# BL808 register map
File version: 0.1
Registers are access not given, no defined reset value unless marked. A register's access mark holds for its fields unless they carry their own. Offsets are from the block's base; [hi:lo] are bit positions; {n}, {i} and the like mark numbered series.

## AUDIO
Base 0x20055000
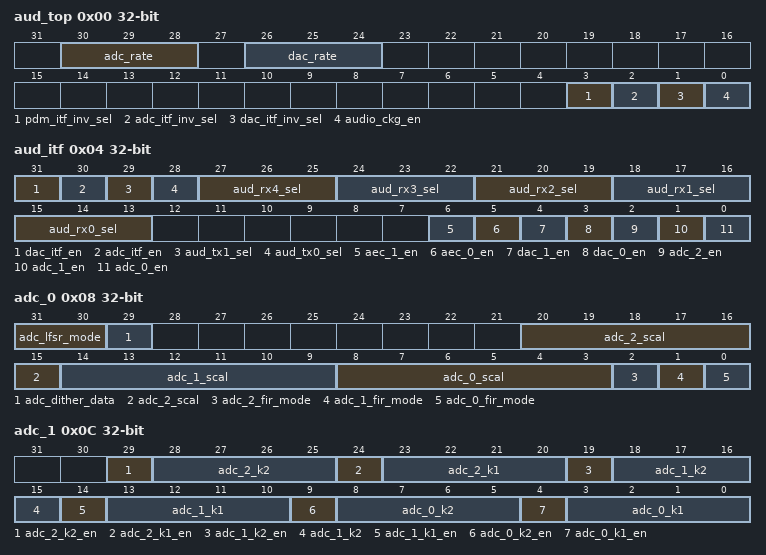
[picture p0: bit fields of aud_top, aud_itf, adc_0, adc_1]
0x00 aud_top
  [30:28] adc_rate rw, [26:24] dac_rate rw, [3] pdm_itf_inv_sel rw, [2] adc_itf_inv_sel rw, [1] dac_itf_inv_sel rw, [0] audio_ckg_en rw
0x04 aud_itf
  [31] dac_itf_en rw, [30] adc_itf_en rw, [29] aud_tx1_sel rw, [28] aud_tx0_sel rw, [3n+15:3n+13] aud_rx{n}_sel rw (n=0..4), [6] aec_1_en rw, [5] aec_0_en rw, [4] dac_1_en rw, [3] dac_0_en rw, [2] adc_2_en rw, [1] adc_1_en rw, [0] adc_0_en rw
0x08 adc_0
  [31:30] adc_lfsr_mode rw, [29] adc_dither_data ro, [20:15] adc_2_scal rw, [14:9] adc_1_scal rw, [8:3] adc_0_scal rw, [2] adc_2_fir_mode rw, [1] adc_1_fir_mode rw, [0] adc_0_fir_mode rw
0x0C adc_1
  [29] adc_2_k2_en rw, [28:25] adc_2_k2 rw, [24] adc_2_k1_en rw, [23:20] adc_2_k1 rw, [19] adc_1_k2_en rw, [18:15] adc_1_k2 rw, [14] adc_1_k1_en rw, [13:10] adc_1_k1 rw, [9] adc_0_k2_en rw, [8:5] adc_0_k2 rw, [4] adc_0_k1_en rw, [3:0] adc_0_k1 rw
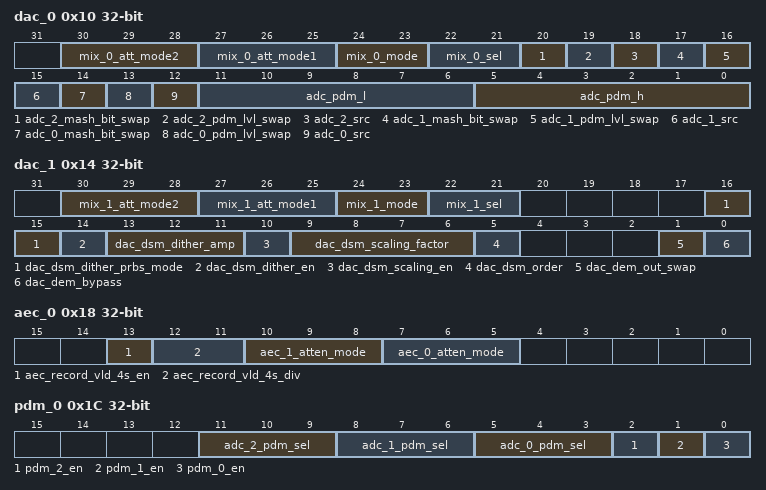
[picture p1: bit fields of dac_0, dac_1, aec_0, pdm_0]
0x10 dac_0
  [30:28] mix_0_att_mode2 rw, [27:25] mix_0_att_mode1 rw, [24:23] mix_0_mode rw, [22:21] mix_0_sel rw, [20] adc_2_mash_bit_swap rw, [19] adc_2_pdm_lvl_swap rw, [18] adc_2_src rw, [17] adc_1_mash_bit_swap rw, [16] adc_1_pdm_lvl_swap rw, [15] adc_1_src rw, [14] adc_0_mash_bit_swap rw, [13] adc_0_pdm_lvl_swap rw, [12] adc_0_src rw, [11:6] adc_pdm_l rw, [5:0] adc_pdm_h rw
0x14 dac_1
  [30:28] mix_1_att_mode2 rw, [27:25] mix_1_att_mode1 rw, [24:23] mix_1_mode rw, [22:21] mix_1_sel rw, [16:15] dac_dsm_dither_prbs_mode rw, [14] dac_dsm_dither_en rw, [13:11] dac_dsm_dither_amp rw, [10] dac_dsm_scaling_en rw, [9:6] dac_dsm_scaling_factor rw, [5] dac_dsm_order rw, [1] dac_dem_out_swap rw, [0] dac_dem_bypass rw
0x18 aec_0
  [13] aec_record_vld_4s_en rw, [12:11] aec_record_vld_4s_div rw, [10:8] aec_1_atten_mode rw, [7:5] aec_0_atten_mode rw
0x1C pdm_0
  [11:9] adc_2_pdm_sel rw, [8:6] adc_1_pdm_sel rw, [5:3] adc_0_pdm_sel rw, [2] pdm_2_en rw, [1] pdm_1_en rw, [0] pdm_0_en rw
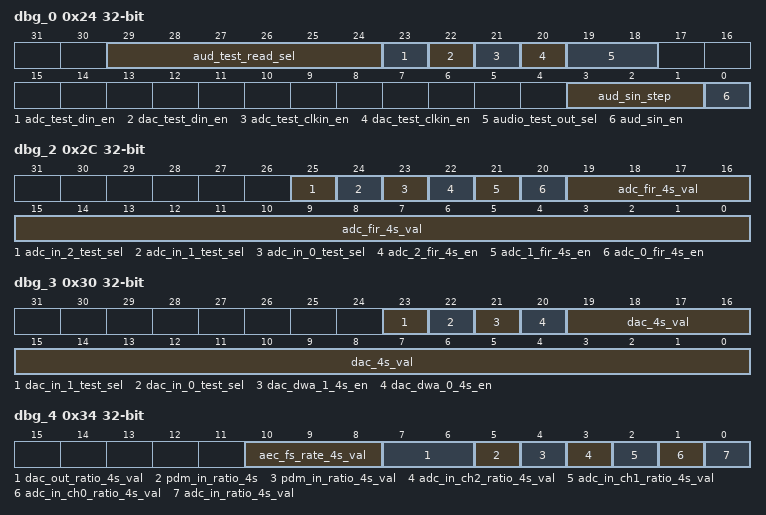
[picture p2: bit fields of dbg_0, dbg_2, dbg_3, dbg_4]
0x24 dbg_0
  [29:24] aud_test_read_sel rw, [23] adc_test_din_en rw, [22] dac_test_din_en rw, [21] adc_test_clkin_en rw, [20] dac_test_clkin_en rw, [19:18] audio_test_out_sel rw, [3:1] aud_sin_step rw, [0] aud_sin_en rw
0x28 dbg_1 ro
  [31:0] aud_test_read
0x2C dbg_2
  [25] adc_in_2_test_sel rw, [24] adc_in_1_test_sel rw, [23] adc_in_0_test_sel rw, [22] adc_2_fir_4s_en rw, [21] adc_1_fir_4s_en rw, [20] adc_0_fir_4s_en rw, [19:0] adc_fir_4s_val rw
0x30 dbg_3
  [23] dac_in_1_test_sel rw, [22] dac_in_0_test_sel rw, [21] dac_dwa_1_4s_en rw, [20] dac_dwa_0_4s_en rw, [19:0] dac_4s_val rw
0x34 dbg_4
  [10:8] aec_fs_rate_4s_val rw, [7:6] dac_out_ratio_4s_val rw, [5] pdm_in_ratio_4s rw, [4] pdm_in_ratio_4s_val rw, [3] adc_in_ch2_ratio_4s_val rw, [2] adc_in_ch1_ratio_4s_val rw, [1] adc_in_ch0_ratio_4s_val rw, [0] adc_in_ratio_4s_val rw
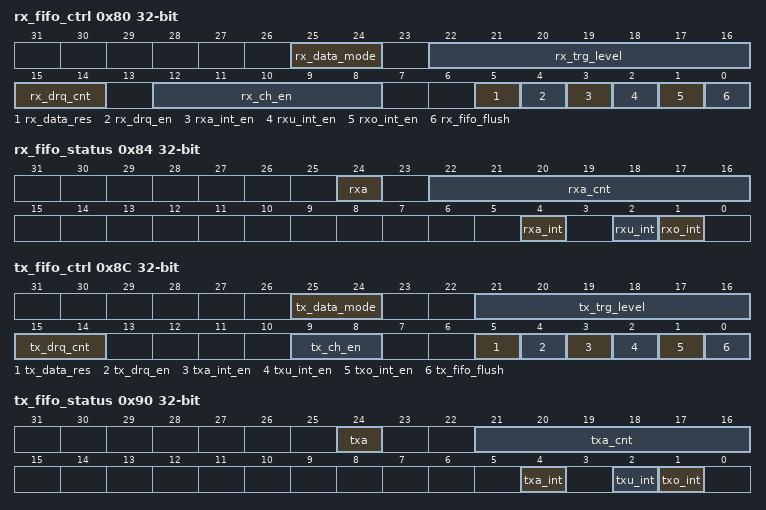
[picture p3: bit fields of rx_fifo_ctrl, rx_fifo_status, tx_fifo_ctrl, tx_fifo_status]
0x80 rx_fifo_ctrl
  [25:24] rx_data_mode rw, [22:16] rx_trg_level rw, [15:14] rx_drq_cnt rw, [12:8] rx_ch_en rw, [5] rx_data_res rw, [4] rx_drq_en rw, [3] rxa_int_en rw, [2] rxu_int_en rw, [1] rxo_int_en rw, [0] rx_fifo_flush write-once
0x84 rx_fifo_status
  [24] rxa ro, [22:16] rxa_cnt ro, [4] rxa_int ro, [2] rxu_int ro, [1] rxo_int ro
0x88 rx_fifo_data ro
  [31:0] rx_data
0x8C tx_fifo_ctrl
  [25:24] tx_data_mode rw, [21:16] tx_trg_level rw, [15:14] tx_drq_cnt rw, [9:8] tx_ch_en rw, [5] tx_data_res rw, [4] tx_drq_en rw, [3] txa_int_en rw, [2] txu_int_en rw, [1] txo_int_en rw, [0] tx_fifo_flush write-once
0x90 tx_fifo_status
  [24] txa ro, [21:16] txa_cnt ro, [4] txa_int ro, [2] txu_int ro, [1] txo_int ro
0x94 tx_fifo_data wo
  [31:0] tx_data
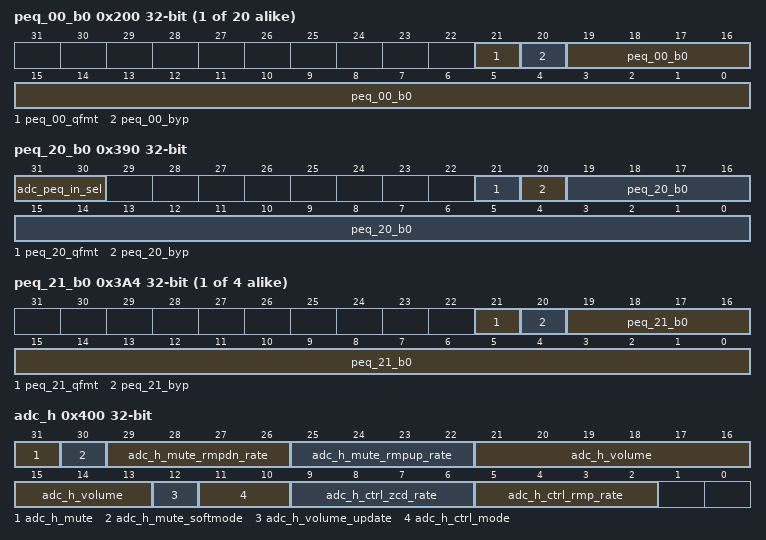
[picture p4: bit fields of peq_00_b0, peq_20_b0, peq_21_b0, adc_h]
{0x200+0x14*i} peq_{i:02}_b0 (i=0..19)
  [21] peq_{i:02}_qfmt rw, [20] peq_{i:02}_byp rw, [19:0] peq_{i:02}_b0 rw
{0x204+0x14*i} peq_{i:02}_b1 (i=0..24)
  [19:0] peq_{i:02}_b1 rw
{0x208+0x14*i} peq_{i:02}_b2 (i=0..24)
  [19:0] peq_{i:02}_b2 rw
{0x20C+0x14*i} peq_{i:02}_a1 (i=0..24)
  [19:0] peq_{i:02}_a1 rw
{0x210+0x14*i} peq_{i:02}_a2 (i=0..24)
  [19:0] peq_{i:02}_a2 rw
0x390 peq_20_b0
  [31:30] adc_peq_in_sel rw, [21] peq_20_qfmt rw, [20] peq_20_byp rw, [19:0] peq_20_b0 rw
{0x200+0x14*i} peq_{i}_b0 (i=21..24)
  [21] peq_{i}_qfmt rw, [20] peq_{i}_byp rw, [19:0] peq_{i}_b0 rw
0x400 adc_h
  [31] adc_h_mute rw, [30] adc_h_mute_softmode rw, [29:26] adc_h_mute_rmpdn_rate rw, [25:22] adc_h_mute_rmpup_rate rw, [21:13] adc_h_volume ro, [12] adc_h_volume_update rw, [11:10] adc_h_ctrl_mode rw, [9:6] adc_h_ctrl_zcd_rate rw, [5:2] adc_h_ctrl_rmp_rate rw
0x404 adc_h_misc
  [31:28] adc_h_ctrl_zcd_timeout rw
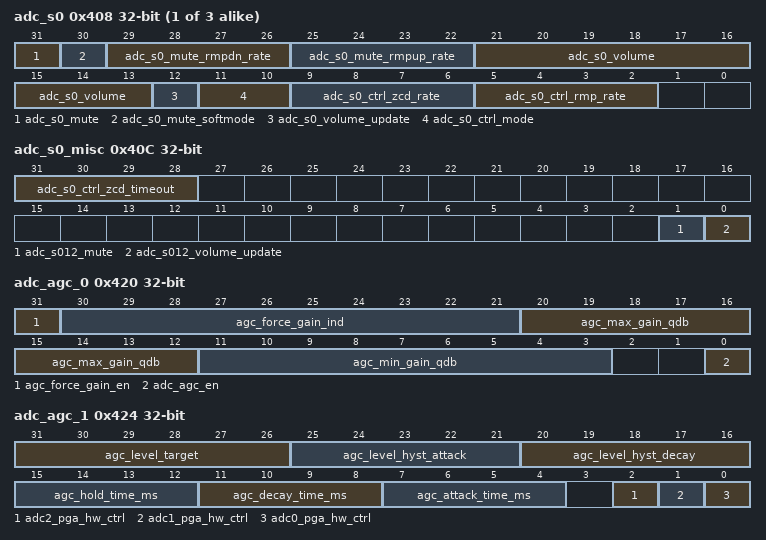
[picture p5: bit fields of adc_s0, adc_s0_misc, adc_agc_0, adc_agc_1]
{0x408+8i} adc_s{i} (i=0..2)
  [31] adc_s{i}_mute rw, [30] adc_s{i}_mute_softmode rw, [29:26] adc_s{i}_mute_rmpdn_rate rw, [25:22] adc_s{i}_mute_rmpup_rate rw, [21:13] adc_s{i}_volume rw, [12] adc_s{i}_volume_update rw, [11:10] adc_s{i}_ctrl_mode rw, [9:6] adc_s{i}_ctrl_zcd_rate rw, [5:2] adc_s{i}_ctrl_rmp_rate rw
0x40C adc_s0_misc
  [31:28] adc_s0_ctrl_zcd_timeout rw, [1] adc_s012_mute rw, [0] adc_s012_volume_update rw
0x414 adc_s1_misc
  [31:28] adc_s1_ctrl_zcd_timeout rw
0x41C adc_s2_misc
  [31:28] adc_s2_ctrl_zcd_timeout rw
0x420 adc_agc_0
  [31] agc_force_gain_en rw, [30:21] agc_force_gain_ind rw, [20:12] agc_max_gain_qdb rw, [11:3] agc_min_gain_qdb rw, [0] adc_agc_en rw
0x424 adc_agc_1
  [31:26] agc_level_target rw, [25:21] agc_level_hyst_attack rw, [20:16] agc_level_hyst_decay rw, [15:12] agc_hold_time_ms rw, [11:8] agc_decay_time_ms rw, [7:4] agc_attack_time_ms rw, [2] adc2_pga_hw_ctrl rw, [1] adc1_pga_hw_ctrl rw, [0] adc0_pga_hw_ctrl rw
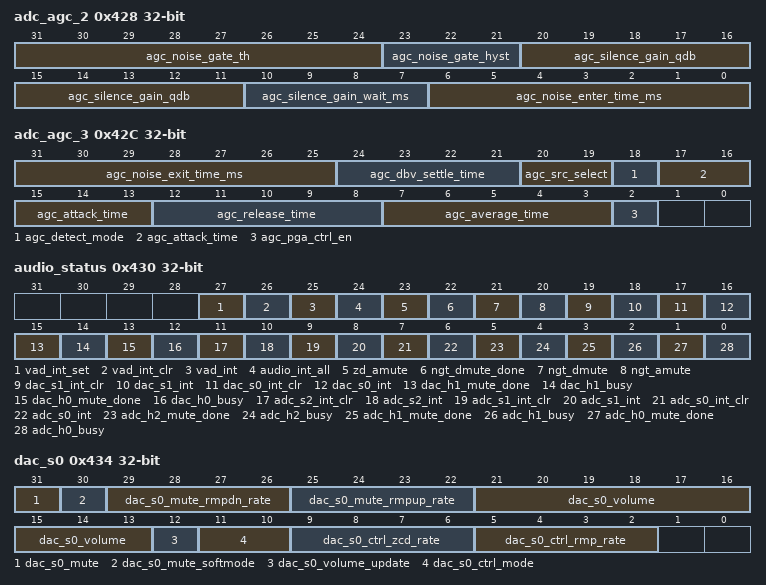
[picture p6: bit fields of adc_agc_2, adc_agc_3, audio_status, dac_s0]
0x428 adc_agc_2 rw
  [31:24] agc_noise_gate_th, [23:21] agc_noise_gate_hyst, [20:11] agc_silence_gain_qdb, [10:7] agc_silence_gain_wait_ms, [6:0] agc_noise_enter_time_ms
0x42C adc_agc_3
  [31:25] agc_noise_exit_time_ms rw, [24:21] agc_dbv_settle_time rw, [20:19] agc_src_select rw, [18] agc_detect_mode rw, [17:13] agc_attack_time rw, [12:8] agc_release_time rw, [7:3] agc_average_time rw, [2] agc_pga_ctrl_en rw
0x430 audio_status
  [27] vad_int_set rw, [26] vad_int_clr rw, [25] vad_int ro, [24] audio_int_all ro, [23] zd_amute ro, [22] ngt_dmute_done ro, [21] ngt_dmute ro, [20] ngt_amute ro, [19] dac_s1_int_clr rw, [18] dac_s1_int ro, [17] dac_s0_int_clr rw, [16] dac_s0_int ro, [15] dac_h1_mute_done ro, [14] dac_h1_busy ro, [13] dac_h0_mute_done ro, [12] dac_h0_busy ro, [11] adc_s2_int_clr rw, [10] adc_s2_int ro, [9] adc_s1_int_clr rw, [8] adc_s1_int ro, [7] adc_s0_int_clr rw, [6] adc_s0_int ro, [5] adc_h2_mute_done ro, [4] adc_h2_busy ro, [3] adc_h1_mute_done ro, [2] adc_h1_busy ro, [1] adc_h0_mute_done ro, [0] adc_h0_busy ro
0x434 dac_s0
  [31] dac_s0_mute rw, [30] dac_s0_mute_softmode rw, [29:26] dac_s0_mute_rmpdn_rate rw, [25:22] dac_s0_mute_rmpup_rate rw, [21:13] dac_s0_volume rw, [12] dac_s0_volume_update rw, [11:10] dac_s0_ctrl_mode rw, [9:6] dac_s0_ctrl_zcd_rate rw, [5:2] dac_s0_ctrl_rmp_rate rw
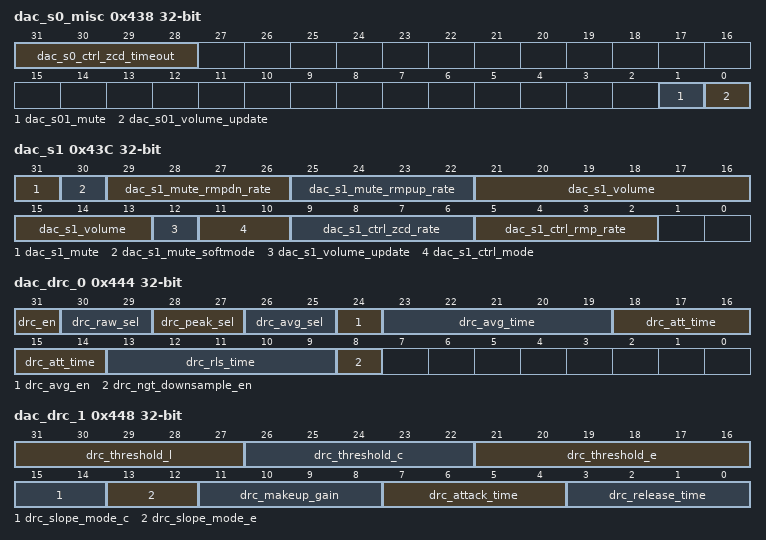
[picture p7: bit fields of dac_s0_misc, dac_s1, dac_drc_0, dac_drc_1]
0x438 dac_s0_misc
  [31:28] dac_s0_ctrl_zcd_timeout rw, [1] dac_s01_mute rw, [0] dac_s01_volume_update rw
0x43C dac_s1
  [31] dac_s1_mute rw, [30] dac_s1_mute_softmode rw, [29:26] dac_s1_mute_rmpdn_rate rw, [25:22] dac_s1_mute_rmpup_rate rw, [21:13] dac_s1_volume rw, [12] dac_s1_volume_update rw, [11:10] dac_s1_ctrl_mode rw, [9:6] dac_s1_ctrl_zcd_rate rw, [5:2] dac_s1_ctrl_rmp_rate rw
0x440 dac_s1_misc
  [31:28] dac_s1_ctrl_zcd_timeout rw
0x444 dac_drc_0
  [31] drc_en rw, [30:29] drc_raw_sel rw, [28:27] drc_peak_sel rw, [26:25] drc_avg_sel rw, [24] drc_avg_en rw, [23:19] drc_avg_time rw, [18:14] drc_att_time rw, [13:9] drc_rls_time rw, [8] drc_ngt_downsample_en rw
0x448 dac_drc_1 rw
  [31:27] drc_threshold_l, [26:22] drc_threshold_c, [21:16] drc_threshold_e, [15:14] drc_slope_mode_c, [13:12] drc_slope_mode_e, [11:8] drc_makeup_gain, [7:4] drc_attack_time, [3:0] drc_release_time
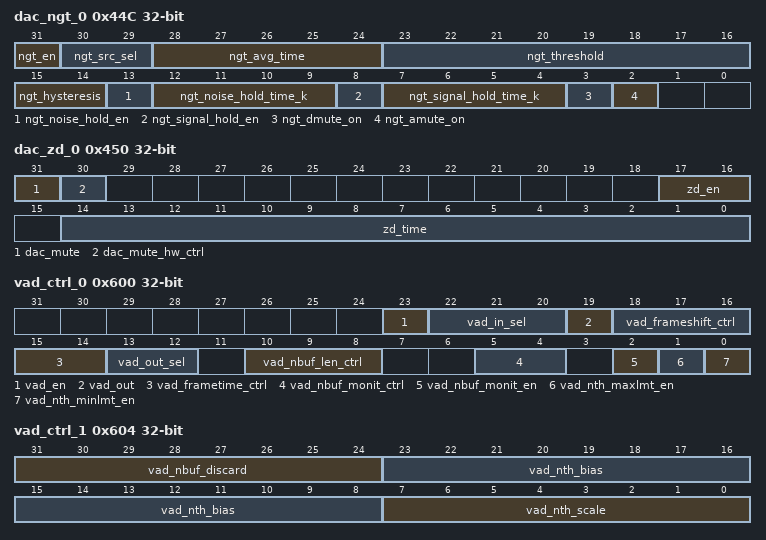
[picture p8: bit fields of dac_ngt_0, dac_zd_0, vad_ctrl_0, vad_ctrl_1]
0x44C dac_ngt_0
  [31] ngt_en rw, [30:29] ngt_src_sel rw, [28:24] ngt_avg_time rw, [23:16] ngt_threshold rw, [15:14] ngt_hysteresis rw, [13] ngt_noise_hold_en rw, [12:9] ngt_noise_hold_time_k rw, [8] ngt_signal_hold_en rw, [7:4] ngt_signal_hold_time_k rw, [3] ngt_dmute_on rw, [2] ngt_amute_on rw
0x450 dac_zd_0
  [31] dac_mute rw, [30] dac_mute_hw_ctrl rw, [17:16] zd_en rw, [14:0] zd_time rw
0x600 vad_ctrl_0
  [23] vad_en rw, [22:20] vad_in_sel rw, [19] vad_out ro, [18:16] vad_frameshift_ctrl rw, [15:14] vad_frametime_ctrl rw, [13:12] vad_out_sel rw, [10:8] vad_nbuf_len_ctrl rw, [5:4] vad_nbuf_monit_ctrl rw, [2] vad_nbuf_monit_en rw, [1] vad_nth_maxlmt_en rw, [0] vad_nth_minlmt_en rw
0x604 vad_ctrl_1 rw
  [31:24] vad_nbuf_discard, [23:8] vad_nth_bias, [7:0] vad_nth_scale
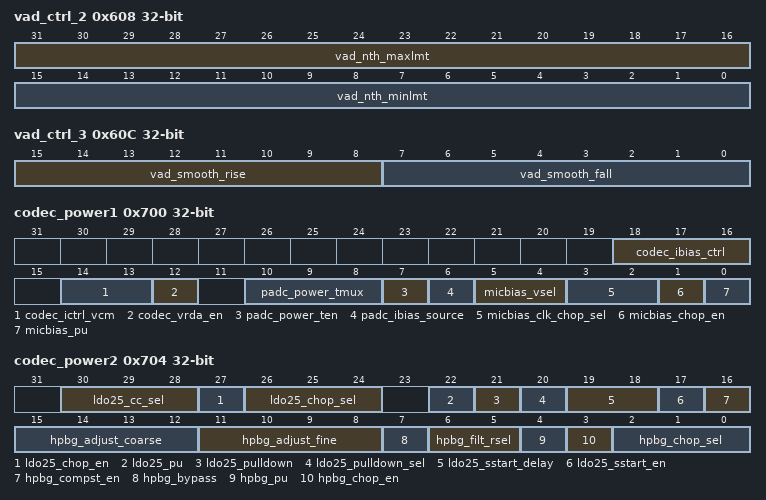
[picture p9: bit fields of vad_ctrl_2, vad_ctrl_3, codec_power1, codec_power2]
0x608 vad_ctrl_2 rw
  [31:16] vad_nth_maxlmt, [15:0] vad_nth_minlmt
0x60C vad_ctrl_3
  [15:8] vad_smooth_rise rw, [7:0] vad_smooth_fall rw
0x610 vad_ctrl_4
  [23:0] vad_ek ro
0x614 vad_ctrl_5
  [23:0] vad_noise_th ro
0x700 codec_power1
  [18:16] codec_ibias_ctrl rw, [14:13] codec_ictrl_vcm rw, [12] codec_vrda_en rw, [10:8] padc_power_tmux rw, [7] padc_power_ten rw, [6] padc_ibias_source rw, [5:4] micbias_vsel rw, [3:2] micbias_clk_chop_sel rw, [1] micbias_chop_en rw, [0] micbias_pu rw
0x704 codec_power2
  [30:28] ldo25_cc_sel rw, [27] ldo25_chop_en rw, [26:24] ldo25_chop_sel rw, [22] ldo25_pu rw, [21] ldo25_pulldown rw, [20] ldo25_pulldown_sel rw, [19:18] ldo25_sstart_delay rw, [17] ldo25_sstart_en rw, [16] hpbg_compst_en rw, [15:12] hpbg_adjust_coarse rw, [11:8] hpbg_adjust_fine rw, [7] hpbg_bypass rw, [6:5] hpbg_filt_rsel rw, [4] hpbg_pu rw, [3] hpbg_chop_en rw, [2:0] hpbg_chop_sel rw
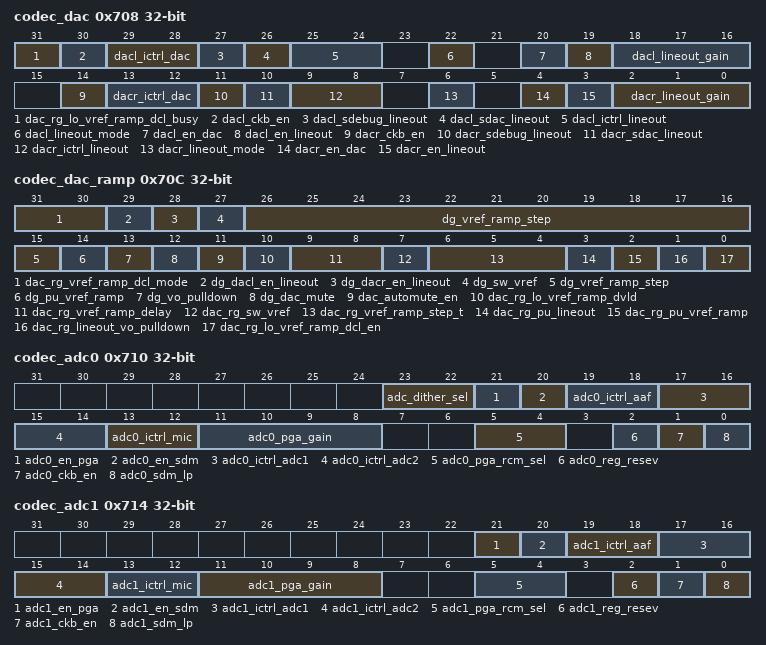
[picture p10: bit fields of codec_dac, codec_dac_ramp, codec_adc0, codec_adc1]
0x708 codec_dac
  [31] dac_rg_lo_vref_ramp_dcl_busy ro, [30] dacl_ckb_en rw, [29:28] dacl_ictrl_dac rw, [27] dacl_sdebug_lineout rw, [26] dacl_sdac_lineout rw, [25:24] dacl_ictrl_lineout rw, [22] dacl_lineout_mode rw, [20] dacl_en_dac rw, [19] dacl_en_lineout rw, [18:16] dacl_lineout_gain rw, [14] dacr_ckb_en rw, [13:12] dacr_ictrl_dac rw, [11] dacr_sdebug_lineout rw, [10] dacr_sdac_lineout rw, [9:8] dacr_ictrl_lineout rw, [6] dacr_lineout_mode rw, [4] dacr_en_dac rw, [3] dacr_en_lineout rw, [2:0] dacr_lineout_gain rw
0x70C codec_dac_ramp access per field
  [31:30] dac_rg_vref_ramp_dcl_mode rw, [29] dg_dacl_en_lineout ro, [28] dg_dacr_en_lineout ro, [27] dg_sw_vref ro, [26:15] dg_vref_ramp_step ro, [14] dg_pu_vref_ramp ro, [13] dg_vo_pulldown ro, [12] dg_dac_mute ro, [11] dac_automute_en rw, [10] dac_rg_lo_vref_ramp_dvld ro, [9:8] dac_rg_vref_ramp_delay rw, [7] dac_rg_sw_vref rw, [6:4] dac_rg_vref_ramp_step_t rw, [3] dac_rg_pu_lineout rw, [2] dac_rg_pu_vref_ramp rw, [1] dac_rg_lineout_vo_pulldown rw, [0] dac_rg_lo_vref_ramp_dcl_en rw
0x710 codec_adc0
  [23:22] adc_dither_sel rw, [21] adc0_en_pga rw, [20] adc0_en_sdm rw, [19:18] adc0_ictrl_aaf rw, [17:16] adc0_ictrl_adc1 rw, [15:14] adc0_ictrl_adc2 rw, [13:12] adc0_ictrl_mic rw, [11:8] adc0_pga_gain rw, [5:4] adc0_pga_rcm_sel rw, [2] adc0_reg_resev rw, [1] adc0_ckb_en rw, [0] adc0_sdm_lp rw
0x714 codec_adc1
  [21] adc1_en_pga rw, [20] adc1_en_sdm rw, [19:18] adc1_ictrl_aaf rw, [17:16] adc1_ictrl_adc1 rw, [15:14] adc1_ictrl_adc2 rw, [13:12] adc1_ictrl_mic rw, [11:8] adc1_pga_gain rw, [5:4] adc1_pga_rcm_sel rw, [2] adc1_reg_resev rw, [1] adc1_ckb_en rw, [0] adc1_sdm_lp rw
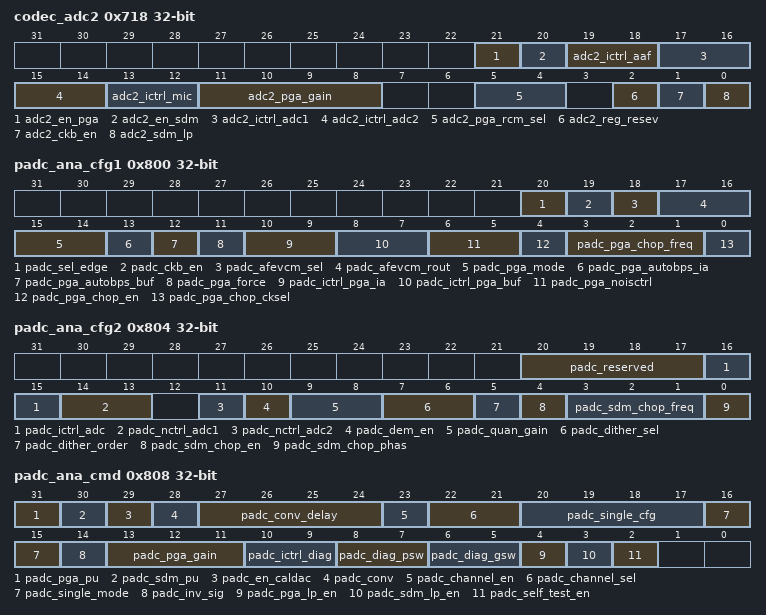
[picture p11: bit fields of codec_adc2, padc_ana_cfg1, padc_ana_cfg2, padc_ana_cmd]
0x718 codec_adc2
  [21] adc2_en_pga rw, [20] adc2_en_sdm rw, [19:18] adc2_ictrl_aaf rw, [17:16] adc2_ictrl_adc1 rw, [15:14] adc2_ictrl_adc2 rw, [13:12] adc2_ictrl_mic rw, [11:8] adc2_pga_gain rw, [5:4] adc2_pga_rcm_sel rw, [2] adc2_reg_resev rw, [1] adc2_ckb_en rw, [0] adc2_sdm_lp rw
0x800 padc_ana_cfg1
  [20] padc_sel_edge rw, [19] padc_ckb_en rw, [18] padc_afevcm_sel rw, [17:16] padc_afevcm_rout rw, [15:14] padc_pga_mode rw, [13] padc_pga_autobps_ia rw, [12] padc_pga_autobps_buf rw, [11] padc_pga_force rw, [10:9] padc_ictrl_pga_ia rw, [8:7] padc_ictrl_pga_buf rw, [6:5] padc_pga_noisctrl rw, [4] padc_pga_chop_en rw, [3:1] padc_pga_chop_freq rw, [0] padc_pga_chop_cksel rw
0x804 padc_ana_cfg2
  [20:17] padc_reserved rw, [16:15] padc_ictrl_adc rw, [14:13] padc_nctrl_adc1 rw, [11] padc_nctrl_adc2 rw, [10] padc_dem_en rw, [9:8] padc_quan_gain rw, [7:6] padc_dither_sel rw, [5] padc_dither_order rw, [4] padc_sdm_chop_en rw, [3:1] padc_sdm_chop_freq rw, [0] padc_sdm_chop_phas rw
0x808 padc_ana_cmd
  [31] padc_pga_pu rw, [30] padc_sdm_pu rw, [29] padc_en_caldac rw, [28] padc_conv rw, [27:24] padc_conv_delay rw, [23] padc_channel_en rw, [22:21] padc_channel_sel rw, [20:17] padc_single_cfg rw, [16:15] padc_single_mode rw, [14] padc_inv_sig rw, [13:11] padc_pga_gain rw, [10:9] padc_ictrl_diag rw, [8:7] padc_diag_psw rw, [6:5] padc_diag_gsw rw, [4] padc_pga_lp_en rw, [3] padc_sdm_lp_en rw, [2] padc_self_test_en rw
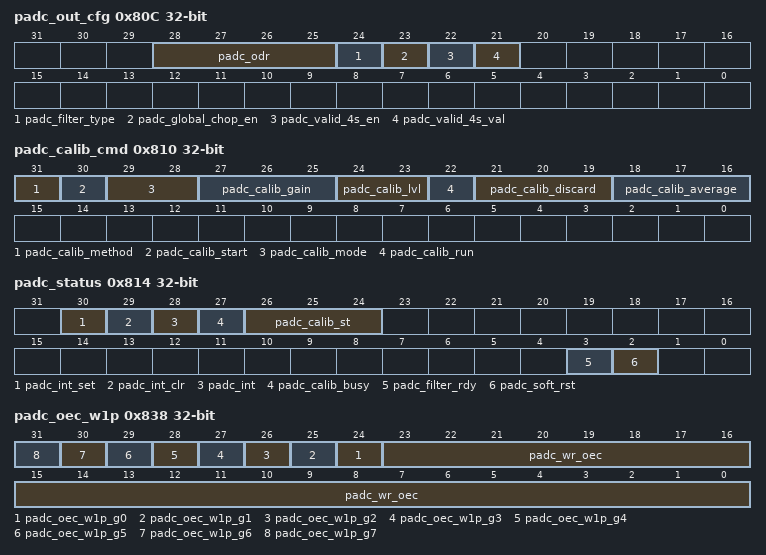
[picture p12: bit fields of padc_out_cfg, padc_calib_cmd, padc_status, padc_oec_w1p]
0x80C padc_out_cfg
  [28:25] padc_odr rw, [24] padc_filter_type rw, [23] padc_global_chop_en rw, [22] padc_valid_4s_en rw, [21] padc_valid_4s_val rw
0x810 padc_calib_cmd
  [31] padc_calib_method rw, [30] padc_calib_start write-once, [29:28] padc_calib_mode rw, [27:25] padc_calib_gain rw, [24:23] padc_calib_lvl rw, [22] padc_calib_run rw, [21:19] padc_calib_discard rw, [18:16] padc_calib_average rw
0x814 padc_status
  [30] padc_int_set rw, [29] padc_int_clr rw, [28] padc_int ro, [27] padc_calib_busy ro, [26:24] padc_calib_st ro, [3] padc_filter_rdy ro, [2] padc_soft_rst rw
0x818 padc_data
  [23:0] padc_raw_data ro
0x81C padc_calib_cfg1
  [23:0] padc_oec ro
0x820 padc_calib_cfg2
  [23:0] padc_gec ro
0x824 padc_calib_cfg3
0x828 padc_calib_cfg4
0x82C padc_calib_cfg5
  [23:0] padc_gaincal_ref rw
0x830 padc_calib_cfg6
0x834 padc_calib_cfg7
0x838 padc_oec_w1p access per field
  [n+24] padc_oec_w1p_g{n} write-once (n=0..7), [23:0] padc_wr_oec rw
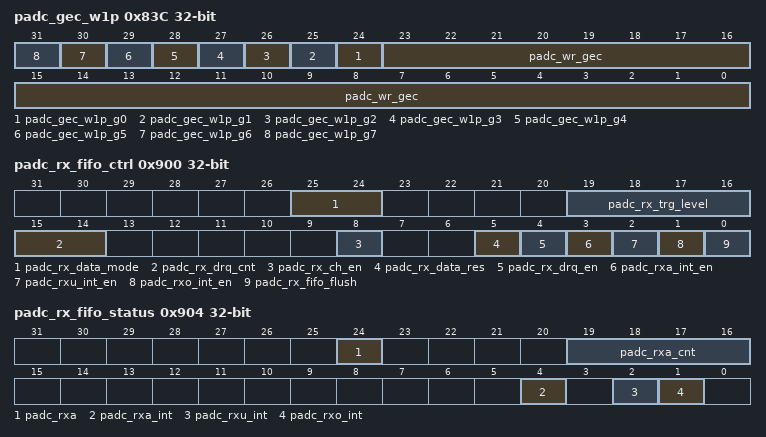
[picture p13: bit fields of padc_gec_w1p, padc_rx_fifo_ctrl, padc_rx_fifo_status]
0x83C padc_gec_w1p access per field
  [n+24] padc_gec_w1p_g{n} write-once (n=0..7), [23:0] padc_wr_gec rw
{0x840+4i} padc_oec_cfg{i} (i=0..7)
  [23:0] padc_oec_g{i} ro
{0x860+4i} padc_gec_cfg{i} (i=0..7)
  [23:0] padc_gec_g{i} ro
0x900 padc_rx_fifo_ctrl
  [25:24] padc_rx_data_mode rw, [19:16] padc_rx_trg_level rw, [15:14] padc_rx_drq_cnt rw, [8] padc_rx_ch_en rw, [5] padc_rx_data_res rw, [4] padc_rx_drq_en rw, [3] padc_rxa_int_en rw, [2] padc_rxu_int_en rw, [1] padc_rxo_int_en rw, [0] padc_rx_fifo_flush write-once
0x904 padc_rx_fifo_status
  [24] padc_rxa ro, [19:16] padc_rxa_cnt ro, [4] padc_rxa_int ro, [2] padc_rxu_int ro, [1] padc_rxo_int ro
0x908 padc_rx_fifo_data ro
  [31:0] padc_rx_data
